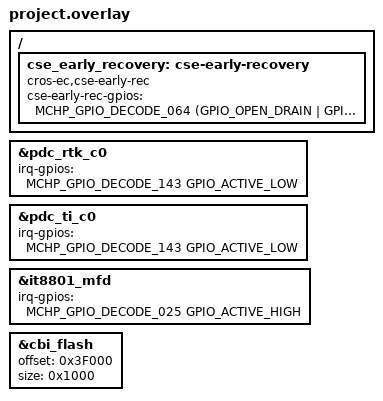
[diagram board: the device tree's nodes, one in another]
/* Copyright 2025 The ChromiumOS Authors
 * Use of this source code is governed by a BSD-style license that can be
 * found in the LICENSE file.
 */

/* ocelot program common DTS includes */

#include <cros/cbi_flash.dtsi>
#include <cros/integrated_fwid.dtsi>

/* ocelot_mchp project DTS includes */

#include "adc.dtsi"
#include "gpio.dtsi"
#include "fan.dtsi"
#include "i2c.dtsi"
#include "power_signals.dtsi"
#include "vci.dtsi"

#include "../rvp_battery.dtsi"
#include "../rvp_interrupts.dtsi"
#include "../rvp_ioex_gpio.dtsi"
#include "../rvp_temp_sensors.dtsi"
#include "../rvp_usbc.dtsi"

#include <ite/it8801-common-cfg.dtsi>

/ {
	cse_early_recovery: cse-early-recovery {
		compatible = "cros-ec,cse-early-rec";
		cse-early-rec-gpios = <MCHP_GPIO_DECODE_064 (GPIO_OPEN_DRAIN | GPIO_ACTIVE_HIGH)>;
	};
};

/* ocelot_mchp overrides follow... */

&pdc_rtk_c0 {
	/* TYPEC_EC_SMBUS_ALERT_0_R */
	irq-gpios = <MCHP_GPIO_DECODE_143 GPIO_ACTIVE_LOW>;
};

&pdc_ti_c0 {
	/* TYPEC_EC_SMBUS_ALERT_0_R */
	irq-gpios = <MCHP_GPIO_DECODE_143 GPIO_ACTIVE_LOW>;
};

/* Use only port C0 */
/delete-node/ &pdc_rtk_c1;
/delete-node/ &pdc_ti_c1;
/delete-node/ &usbc_port1;

&it8801_mfd {
	irq-gpios = <MCHP_GPIO_DECODE_025 GPIO_ACTIVE_HIGH>;
};

&cbi_flash {
       offset = <0x3F000>;
       size = <0x1000>;
};

/* Disable nodes for features not yet enabled. */
/delete-node/ &int_tablet_mode;
/delete-node/ &i2c_port_ish;
